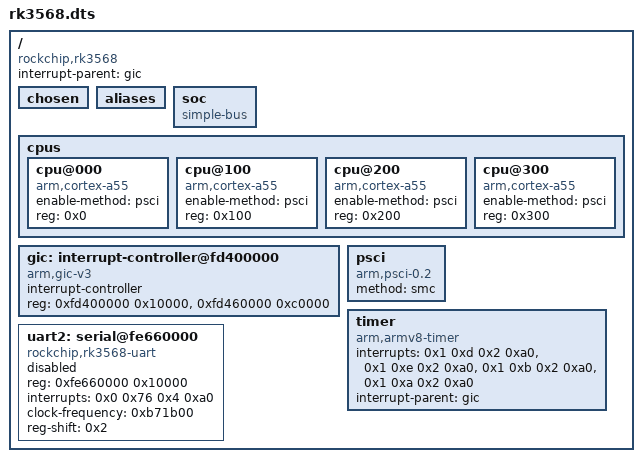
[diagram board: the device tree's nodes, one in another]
/dts-v1/;

/ {
	#address-cells = < 0x1 >;
	#size-cells = < 0x1 >;
	compatible = "rockchip,rk3568";
	interrupt-parent = < &gic >;
	chosen {
	};
	aliases {
	};
	soc {
		#address-cells = < 0x1 >;
		#size-cells = < 0x1 >;
		compatible = "simple-bus";
		ranges;
	};
	cpus {
		#address-cells = < 0x1 >;
		#size-cells = < 0x0 >;
		cpu@000 {
			device_type = "cpu";
			compatible = "arm,cortex-a55";
			enable-method = "psci";
			reg = < 0x0 >;
		};
		cpu@100 {
			device_type = "cpu";
			compatible = "arm,cortex-a55";
			enable-method = "psci";
			reg = < 0x100 >;
		};
		cpu@200 {
			device_type = "cpu";
			compatible = "arm,cortex-a55";
			enable-method = "psci";
			reg = < 0x200 >;
		};
		cpu@300 {
			device_type = "cpu";
			compatible = "arm,cortex-a55";
			enable-method = "psci";
			reg = < 0x300 >;
		};
	};
	gic: interrupt-controller@fd400000 {
		#address-cells = < 0x1 >;
		compatible = "arm,gic-v3", "arm,gic";
		#interrupt-cells = < 0x4 >;
		interrupt-controller;
		reg = < 0xfd400000 0x10000 >, < 0xfd460000 0xc0000 >;
		status = "okay";
		phandle = < 0x1 >;
	};
	psci {
		compatible = "arm,psci-0.2", "arm,psci";
		method = "smc";
	};
	timer {
		compatible = "arm,armv8-timer";
		interrupts = < 0x1 0xd 0x2 0xa0 >, < 0x1 0xe 0x2 0xa0 >, < 0x1 0xb 0x2 0xa0 >, < 0x1 0xa 0x2 0xa0 >;
		interrupt-parent = < &gic >;
	};
	uart2: serial@fe660000 {
		compatible = "rockchip,rk3568-uart", "ns16550";
		reg = < 0xfe660000 0x10000 >;
		interrupts = < 0x0 0x76 0x4 0xa0 >;
		clock-frequency = < 0xb71b00 >;
		reg-shift = < 0x2 >;
		status = "disabled";
	};
};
